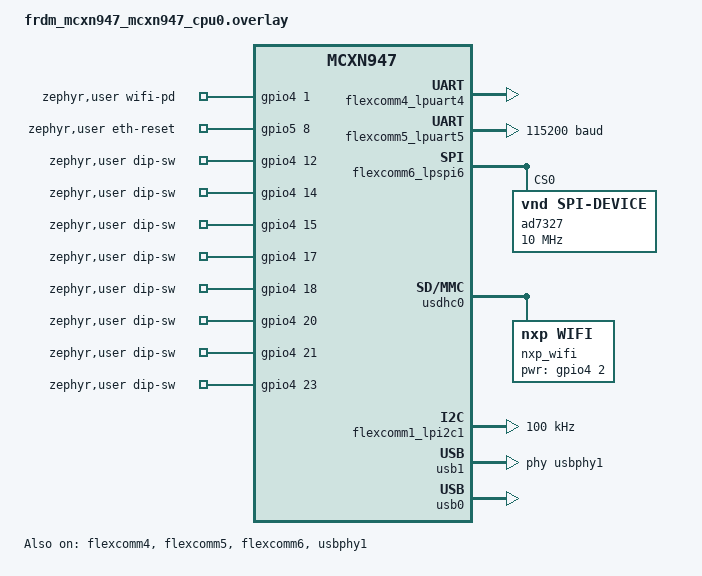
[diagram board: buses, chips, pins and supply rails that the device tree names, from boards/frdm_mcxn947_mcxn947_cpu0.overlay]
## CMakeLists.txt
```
# SPDX-License-Identifier: Apache-2.0

cmake_minimum_required(VERSION 3.20.0)

# boards/frdm_mcxn947_mcxn947_cpu0.overlay — Zephyr 자동 인식 (별도 지정 불필요)
find_package(Zephyr REQUIRED HINTS $ENV{ZEPHYR_BASE})
project(SmartGateway)

# USB HOST 스택 활성 시 링커가 __rom_start_address 심볼을 요구하나
# Zephyr 빌드 시스템이 defsym을 제공하지 않아 명시적으로 정의
if(CONFIG_USB_HOST_STACK)
  zephyr_ld_options(-Wl,--defsym=__rom_start_address=0x10000000)
endif()

target_sources(app PRIVATE src/main.c src/adc.c src/udp.c src/msgpack_adc.c src/time_helper.c src/rs232.c src/tcp_gateway.c src/sync_gate.c src/gw_error.c)

target_sources(app PRIVATE src/config_nvs.c src/network_manager.c src/dip_switch.c)

if(CONFIG_SMARTGATEWAY_DI_DO_ENABLE)
  target_sources(app PRIVATE src/di_do.c)
endif()

if(CONFIG_USB_HOST_STACK)
  target_sources(app PRIVATE src/ftdi_usb.c src/gas_sensor.c)
  # usbh_device.h (internal header) for usbh_device_get_any
  zephyr_include_directories(
    ${ZEPHYR_BASE}/subsys/usb/host
  )
endif()

if(CONFIG_SMARTGATEWAY_WIFI_ENABLE)
  target_sources(app PRIVATE src/wifi_manager.c)
endif()

# NXP WiFi 미들웨어(mlan_sdio.c, wlan.c)가 fsl_gpio.h 를 include 하지만
# wifi_nxp/CMakeLists.txt 에 drivers/gpio 경로가 없음.
# MCXN947 GPIO = nxp,kinetis-gpio → drivers/gpio/fsl_gpio.h 를 전역으로 추가.
if(CONFIG_WIFI_NXP)
  zephyr_include_directories(
    ${ZEPHYR_HAL_NXP_MODULE_DIR}/mcux/mcux-sdk-ng/drivers/gpio
  )
endif()
```

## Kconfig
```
# SPDX-License-Identifier: Apache-2.0
#
# SmartGateway 앱 옵션 — west build 전 menuconfig / prj.conf 로 조정

menu "SmartGateway"

config SMARTGATEWAY_LINE_ID
	string "UDP/MessagePack line / DeviceID (최대 50자)"
	default "HL-MAND-SENSOR-001"
	help
	  line·DeviveID 필드에 쓰입니다. 50자 초과는 잘립니다(NUL 종료).
	  prj.conf 예: CONFIG_SMARTGATEWAY_LINE_ID="이름"

comment "── NVS 분할 부팅 (net_boot_mode) ───────────────"

config SMARTGATEWAY_NET_BOOT_DEFAULT
	int "NVS 기본 네트워크 모드 (0=WiFi 1=이더넷)"
	default 0
	range 0 1
	help
	  스키마 초기화 후 또는 load_defaults 시 NVS에 쓰이는 초기값.
	  0=WiFi: 유선 내리고 WiFi만 시도. 전부 실패 시 NVS를 1로 바꾸고 냉 재부팅.
	  1=이더넷: WiFi 단계 없음.
	  WiFi 비활성 빌드에서는 항상 이더넷(1)으로 고정된다.

config SMARTGATEWAY_FORCE_ETH_BOOT_MODE
	bool "부팅 시 NVS net_boot_mode를 이더넷(1)로 저장"
	default n
	help
	  한 번 플래시 후 재부팅하면 NVS가 유선 우선 모드로 덮어써진다.
	  FORCE_WIFI_BOOT_MODE 와 동시에 사용할 수 없음(menuconfig 가 배타 처리).

config SMARTGATEWAY_FORCE_WIFI_BOOT_MODE
	bool "부팅 시 NVS net_boot_mode를 WiFi(0)로 저장"
	default n
	depends on SMARTGATEWAY_WIFI_ENABLE
	depends on !SMARTGATEWAY_FORCE_ETH_BOOT_MODE
	help
	  한 번 빌드·플래시 후 재부팅하면 NVS의 분할 부팅 모드가 WiFi로 덮어써진다.
	  WiFi 테스트 후에는 이 옵션을 끄고 다시 빌드하면 된다.

comment "── 이더넷 UDP ──────────────────────────────────"

config SMARTGATEWAY_ETH_UDP_PEER_IP
	string "이더넷 UDP 전송 목적지 IPv4"
	default "10.108.214.100"
	help
	  이더넷 인터페이스로 ADC 패킷을 보낼 상대 주소.
	  prj.conf: CONFIG_SMARTGATEWAY_ETH_UDP_PEER_IP="x.x.x.x"

config SMARTGATEWAY_ETH_UDP_PEER_PORT
	int "이더넷 UDP 전송 목적지 포트"
	default 20263
	range 1 65535

config SMARTGATEWAY_ETH_UDP_BIND_PORT
	int "이더넷 UDP 수신 바인드 포트 (0이면 recv 안 함)"
	default 0
	range 0 65535

comment "── 이더넷 보드 IP·TCP 상대 (netmgr / NVS 기본값) ──"

config SMARTGATEWAY_ETH_STATIC_IP
	string "이더넷 인터페이스 정적 IPv4 (보드)"
	default "10.108.214.150"

config SMARTGATEWAY_ETH_STATIC_NETMASK
	string "이더넷 서브넷 마스크"
	default "255.255.255.0"

config SMARTGATEWAY_ETH_STATIC_GW
	string "이더넷 기본 게이트웨이"
	default "10.108.214.1"

config SMARTGATEWAY_ETH_TCP_PEER_IP
	string "이더넷 TCP 상대(서버) IPv4"
	default "10.108.214.100"
	help
	  NVS의 eth_tcp_server_ip 기본값. TCP Modbus 게이트가 listen 할 때 상대 PC 주소.

config SMARTGATEWAY_ETH_TCP_PEER_PORT
	int "이더넷 TCP 상대 포트"
	default 20273
	range 1 65535

comment "── WiFi UDP ─────────────────────────────────────"

config SMARTGATEWAY_WIFI_UDP_PEER_IP
	string "WiFi UDP 전송 목적지 IPv4"
	default "192.168.5.100"
	help
	  WiFi 인터페이스로 ADC 패킷을 보낼 상대 주소.
	  prj.conf: CONFIG_SMARTGATEWAY_WIFI_UDP_PEER_IP="x.x.x.x"

config SMARTGATEWAY_WIFI_UDP_PEER_PORT
	int "WiFi UDP 전송 목적지 포트"
	default 20263
	range 1 65535

config SMARTGATEWAY_WIFI_UDP_BIND_PORT
	int "WiFi UDP 수신 바인드 포트 (0이면 recv 안 함)"
	default 0
	range 0 65535
	help
	  0 보다 크면 해당 포트에 bind 하고 recvfrom 으로 수신합니다.
	  SMARTGATEWAY_TCP_MODBUS_GATEWAY 사용 시 TCP MsgType 0x01(SYNC) 수신 전까지
	  UDP 수신은 하지 않습니다.

config SMARTGATEWAY_UDP_TEST_MODE
	bool "UDP 테스트 페이로드 (MessagePack array 4요소)"
	default n
	help
	  y이면 [ device_str, ts(17자), f32, f32 ] 형태의 MessagePack 배열만 전송합니다.
	  페이로드의 float 두 개는 항상 LPADC에서 읽은 snap->raw[0], raw[1] 실측값입니다.
	  운영(map)은 이 옵션을 끄면 됩니다.
	  prj.conf: CONFIG_SMARTGATEWAY_UDP_TEST_MODE=y

config SMARTGATEWAY_ADC_CHANNEL_COUNT
	int "LPADC 변환 채널 수 (1~8)"
	default 8
	range 1 8
	help
	  adc_task 가 변환하는 채널 개수(0..N-1, adc_inputs[] 와 순서 일치).
	  prj.conf 예: CONFIG_SMARTGATEWAY_ADC_CHANNEL_COUNT=2

config SMARTGATEWAY_RS232_ENABLE
	bool "RS-232 태스크 (UART ↔ MAX3232)"
	default n
	select SERIAL
	help
	  포트 0 = SmartGateway overlay 기준 flexcomm5 LPUART5 (MikroBUS P1_16 RX / P1_17 TX).
	  TCP Modbus 게이트웨이를 끄면 UDP(RS232_UDP_LISTEN_PORT) → UART 패스스루 스레드가 동작합니다.

if SMARTGATEWAY_RS232_ENABLE

config SMARTGATEWAY_RS232_BAUD_RATE
	int "RS-232 UART 보율 (bps)"
	default 115200

choice SMARTGATEWAY_RS232_DATA_BITS_CHOICE
	prompt "RS-232 데이터 비트"
	default SMARTGATEWAY_RS232_DATA_BITS_8
	help
	  기본 8비트 (8N1).

config SMARTGATEWAY_RS232_DATA_BITS_7
	bool "7"

config SMARTGATEWAY_RS232_DATA_BITS_8
	bool "8"
endchoice

choice SMARTGATEWAY_RS232_PARITY_CHOICE
	prompt "RS-232 패리티"
	default SMARTGATEWAY_RS232_PARITY_NONE
	help
	  기본 None (8N1).

config SMARTGATEWAY_RS232_PARITY_NONE
	bool "None"

config SMARTGATEWAY_RS232_PARITY_EVEN
	bool "Even"

config SMARTGATEWAY_RS232_PARITY_ODD
	bool "Odd"
endchoice

choice SMARTGATEWAY_RS232_STOP_BITS_CHOICE
	prompt "RS-232 정지 비트"
	default SMARTGATEWAY_RS232_STOP_BITS_1
	help
	  기본 1스톱.

config SMARTGATEWAY_RS232_STOP_BITS_1
	bool "1"

config SMARTGATEWAY_RS232_STOP_BITS_2
	bool "2"
endchoice

choice SMARTGATEWAY_RS232_FLOW_CTRL_CHOICE
	prompt "RS-232 흐름 제어"
	default SMARTGATEWAY_RS232_FLOW_CTRL_NONE
	help
	  기본 None. RTS/CTS는 보드/드라이버 배선이 있을 때만.

config SMARTGATEWAY_RS232_FLOW_CTRL_NONE
	bool "None"

config SMARTGATEWAY_RS232_FLOW_CTRL_RTS_CTS
	bool "RTS/CTS"
endchoice

config SMARTGATEWAY_RS232_UDP_LISTEN_PORT
	int "RS-232 패스스루 UDP 수신 포트 (이 장치에 bind)"
	default 20264
	range 1 65535
	help
	  TCP Modbus 게이트웨이가 꺼져 있을 때, 이 포트로 들어오는 UDP 페이로드를 RS-232 포트 0으로 전달합니다.
	  서버(또는 PC)가 게이트웨이 IP:이 포트로 바이트 스트림을 보내면 됩니다.

config SMARTGATEWAY_RS232_MODBUS_POST_TX_DELAY_MS
	int "Modbus RTU: UART TX 직후 수신 전 지연 (ms, 0=비활성)"
	default 0
	range 0 100
	help
	  RS-485 트랜시버는 TX 후 버스 방향 전환·라인 안착 시간이 필요할 수 있습니다.
	  수 ms 넣으면 슬레이브 첫 바이트 유실을 줄일 때가 있습니다. 풀듀플렉스 RS-232만 쓰면 0 권장.

endif

config SMARTGATEWAY_TCP_MODBUS_GATEWAY
	bool "TCP STX/Len/MsgType/Seq + Body + Error+ETX, RS-232 Modbus 중계"
	default n
	depends on SMARTGATEWAY_RS232_ENABLE
	select NET_TCP
	help
	  외곽 CRC 없음. Header 5B + Body(최대 256) + Tail(Error+ETX).
	  TCP_CLIENT_MODE=n 이면 보드가 listen(서버). y 이면 보드가 peer에 connect(클라이언트).
	  보드(클라이언트): 0x80 CONNECT(마스터+IDX+버전)를 HANDSHAKE_POLL_MS마다 송신.
	  서버: 0x01 SYNC(시각+RS-232). 보드: 0x81 ACK(Ret).
	  세션: 서버 0x02 Modbus 요청 → 보드 0x82(시각+응답).
	  RS-232 백그라운드 스레드(UDP 패스스루)는 띄우지 않습니다.

config SMARTGATEWAY_TCP_CLIENT_MODE
	bool "TCP 클라이언트: 원격 서버에 connect (보드는 클라이언트)"
	default y
	depends on SMARTGATEWAY_TCP_MODBUS_GATEWAY
	help
	  y이면 SMARTGATEWAY_TCP_PEER_IP:PEER_PORT 로 접속합니다. 원격(MCNX947 등)이
	  TCP 서버로 listen 해야 합니다.
	  n이면 SMARTGATEWAY_TCP_BIND_IP:LISTEN_PORT 에서 accept 하는 기존 동작입니다.

config SMARTGATEWAY_TCP_PEER_IP
	string "TCP peer IPv4 (클라이언트 모드: connect 대상 서버)"
	default "192.168.0.1"
	depends on SMARTGATEWAY_TCP_MODBUS_GATEWAY && SMARTGATEWAY_TCP_CLIENT_MODE

config SMARTGATEWAY_TCP_PEER_PORT
	int "TCP peer 포트 (클라이언트 모드)"
	default 5020
	range 1 65535
	depends on SMARTGATEWAY_TCP_MODBUS_GATEWAY && SMARTGATEWAY_TCP_CLIENT_MODE

config SMARTGATEWAY_TCP_RECONNECT_MS
	int "클라이언트: connect 실패·세션 종료 후 재시도 간격 (ms)"
	default 3000
	range 500 600000
	depends on SMARTGATEWAY_TCP_MODBUS_GATEWAY && SMARTGATEWAY_TCP_CLIENT_MODE

comment "── 이더넷 TCP ──────────────────────────────────"

config SMARTGATEWAY_ETH_TCP_BIND_IP
	string "이더넷 TCP listen 바인드 IPv4"
	default "0.0.0.0"
	depends on SMARTGATEWAY_TCP_MODBUS_GATEWAY && !SMARTGATEWAY_TCP_CLIENT_MODE

config SMARTGATEWAY_ETH_TCP_LISTEN_PORT
	int "이더넷 TCP listen 포트"
	default 20273
	range 1 65535
	depends on SMARTGATEWAY_TCP_MODBUS_GATEWAY && !SMARTGATEWAY_TCP_CLIENT_MODE

comment "── WiFi TCP ─────────────────────────────────────"

config SMARTGATEWAY_WIFI_TCP_BIND_IP
	string "WiFi TCP listen 바인드 IPv4"
	default "0.0.0.0"
	depends on SMARTGATEWAY_TCP_MODBUS_GATEWAY && !SMARTGATEWAY_TCP_CLIENT_MODE

config SMARTGATEWAY_WIFI_TCP_LISTEN_PORT
	int "WiFi TCP listen 포트"
	default 20273
	range 1 65535
	depends on SMARTGATEWAY_TCP_MODBUS_GATEWAY && !SMARTGATEWAY_TCP_CLIENT_MODE

config SMARTGATEWAY_PROTO_DEVICE_ID
	int "(예비) 프로토콜 Device ID — 현재 TCP 외곽 프레임에 미사용"
	default 1
	range 0 2147483647
	depends on SMARTGATEWAY_TCP_MODBUS_GATEWAY

config SMARTGATEWAY_TCP_HANDSHAKE_POLL_MS
	int "접속 통보(0x80) 송신 주기·수신 대기 (ms)"
	default 2000
	range 500 60000
	depends on SMARTGATEWAY_TCP_MODBUS_GATEWAY

config SMARTGATEWAY_TCP_CONNECT_MASTER
	string "CONNECT(0x80) Body: 장비 마스터 코드 (일반 문자, ASCII 바이트로 송신)"
	default "KRWJARDU002"
	depends on SMARTGATEWAY_TCP_MODBUS_GATEWAY
	help
	  예: KRWJARDU001 → 전선상 바이트 4B 52 57 … (문자별 ASCII, 덤프에서는 16진으로 보임).
	  NUL 제외·최대 SMARTGATEWAY_TCP_MAX_BODY 범위까지 복사 후 버전 헥사를 이어 붙입니다.
	  prj.conf: CONFIG_SMARTGATEWAY_TCP_CONNECT_MASTER="KRWJARDU001"

config SMARTGATEWAY_TCP_CONNECT_VERSION_HEX
	string "CONNECT(0x80) Body: 버전 등 (마스터 뒤에 이어 붙음, 연속 16진)"
	default "020000"
	depends on SMARTGATEWAY_TCP_MODBUS_GATEWAY
	help
	  기본 020000 = 바이트 02 00 00 (예: 2.0.0). 서버 규격에 맞게 변경.
	  최종 Body = 마스터(ASCII, 가변) + IDX(1B) + 버전(3B, 헥사 디코드). NVS master_code 우선.

config SMARTGATEWAY_TCP_MAX_BODY
	int "외곽 프레임 Body 최대 길이 (바이트, 규격 최대 256)"
	default 256
	range 0 256
	depends on SMARTGATEWAY_TCP_MODBUS_GATEWAY
	help
	  RS-232·TCP Body 상한. TCP_STREAM_BUF 는 (5 + 이 값 + 1) 이상 권장 (STX+Type+Seq+Len_BE+Body+ETX).

config SMARTGATEWAY_TCP_RS232_RX_TIMEOUT_MS
	int "RS-232 응답 수신 최대 대기 (ms, 첫 바이트~프레임 끝)"
	default 800
	range 100 86400000
	depends on SMARTGATEWAY_TCP_MODBUS_GATEWAY
	help
	  장치 자동 응답: 수백 ms. 수동 시험·느린 장치는 3600000(1시간) 등까지 설정 가능.

config SMARTGATEWAY_TCP_RS232_INTER_FRAME_GAP_MS
	int "RS-232 한 프레임 종료: 마지막 바이트 후 무음 시간 (ms)"
	default 50
	range 20 5000
	depends on SMARTGATEWAY_TCP_MODBUS_GATEWAY
	help
	  Modbus RTU 규격은 ~3.5 문자 시간(115200에서 수십 ms 미만). 수동 타이핑·느린 송신이면
	  1000~2000처럼 크게 설정(무음이 이 시간 지나면 수신 완료로 간주).

config SMARTGATEWAY_TCP_STREAM_BUF
	int "TCP 클라이언트 스트림 누적 버퍼 크기"
	default 512
	range 256 8192
	depends on SMARTGATEWAY_TCP_MODBUS_GATEWAY
	help
	  최소 권장: 5 + SMARTGATEWAY_TCP_MAX_BODY + 1 (한 프레임).

config SMARTGATEWAY_TCP_START_DELAY_MS
	int "TCP 게이트웨이 태스크 시작 전 지연 (ms)"
	default 0
	range 0 600000
	depends on SMARTGATEWAY_TCP_MODBUS_GATEWAY
	help
	  부팅 직후 다른 태스크·네트워크 준비 시간 확보용.


comment "보드(이 기기)의 고정 IPv4는 Zephyr 표준 옵션으로 prj.conf 에서 설정합니다:"
comment "  CONFIG_NET_CONFIG_MY_IPV4_ADDR, CONFIG_NET_CONFIG_MY_IPV4_GW, CONFIG_NET_CONFIG_MY_IPV4_NETMASK"

choice SMARTGATEWAY_NET_MODE
	prompt "네트워크 동작 모드"
	default SMARTGATEWAY_NET_MODE_BOTH
	help
	  prj.conf 에서 하나만 =y 로 설정하면 아래 항목이 자동 결정됩니다.
	    이더넷 IP 자동 설정(NET_CONFIG_SETTINGS)
	    WiFi 태스크 빌드(wifi_manager.c)

config SMARTGATEWAY_NET_MODE_ETH_ONLY
	bool "이더넷 전용"
	imply NET_CONFIG_SETTINGS

config SMARTGATEWAY_NET_MODE_WIFI_ONLY
	bool "WiFi 전용"

config SMARTGATEWAY_NET_MODE_BOTH
	bool "이더넷 + WiFi 동시"
	imply NET_CONFIG_SETTINGS

endchoice

config SMARTGATEWAY_WIFI_ENABLE
	bool
	default y if SMARTGATEWAY_NET_MODE_WIFI_ONLY || SMARTGATEWAY_NET_MODE_BOTH
	help
	  SMARTGATEWAY_NET_MODE 에서 자동 결정됩니다. 직접 수정하지 마세요.

if SMARTGATEWAY_WIFI_ENABLE

config SMARTGATEWAY_WIFI_SSID
	string "WiFi AP SSID"
	default "MyWiFi"
	help
	  연결할 AP의 SSID입니다.
	  prj.conf: CONFIG_SMARTGATEWAY_WIFI_SSID="내AP이름"

config SMARTGATEWAY_WIFI_PSK
	string "WiFi AP 비밀번호 (WPA2-PSK / WPA3-SAE 공용)"
	default ""
	help
	  WPA2-PSK 또는 WPA3-SAE 비밀번호. 아래 보안 방식에 따라 psk/sae_password 로 전달됩니다.
	  prj.conf: CONFIG_SMARTGATEWAY_WIFI_PSK="비밀번호"

choice SMARTGATEWAY_WIFI_SECURITY
	prompt "WiFi 보안 방식"
	default SMARTGATEWAY_WIFI_SECURITY_WPA2
	help
	  AP에 맞는 보안 방식을 선택합니다.

config SMARTGATEWAY_WIFI_SECURITY_NONE
	bool "Open (보안 없음)"

config SMARTGATEWAY_WIFI_SECURITY_WPA2
	bool "WPA2-PSK"

config SMARTGATEWAY_WIFI_SECURITY_WPA3
	bool "WPA3-SAE (자동 PWE: H2E + HNP)"

config SMARTGATEWAY_WIFI_SECURITY_WPA_AUTO
	bool "WPA2/WPA3 자동 (전환 AP 호환)"

endchoice

config SMARTGATEWAY_WIFI_STATIC_IP
	string "WiFi 인터페이스 정적 IPv4 주소"
	default "10.108.214.151"
	help
	  이더넷(NET_CONFIG_MY_IPV4_ADDR)과 충돌하지 않도록 별도 IP를 지정합니다.
	  prj.conf: CONFIG_SMARTGATEWAY_WIFI_STATIC_IP="x.x.x.x"

config SMARTGATEWAY_WIFI_STATIC_NETMASK
	string "WiFi 인터페이스 서브넷 마스크"
	default "255.255.255.0"

config SMARTGATEWAY_WIFI_STATIC_GW
	string "WiFi 인터페이스 기본 게이트웨이"
	default "10.108.214.1"

config SMARTGATEWAY_WIFI_TCP_PEER_IP
	string "WiFi TCP 상대(서버) IPv4"
	default "192.168.88.3"
	help
	  NVS의 wifi_tcp_server_ip 기본값.

config SMARTGATEWAY_WIFI_TCP_PEER_PORT
	int "WiFi TCP 상대 포트"
	default 20273
	range 1 65535

config SMARTGATEWAY_DEFER_WIFI_CONNECT_MS
	int "WiFi 연결 시도 전 추가 지연 (ms, 0=없음)"
	default 0
	range 0 600000
	help
	  네트워크 매니저가 WiFi 연결 전 대기하는 시간(RAM/crypto 피크 분산 등).

config SMARTGATEWAY_WIFI_WPA3_TRANSITION_AP
	bool "WPA3 전환(AP 혼합) — wifi 확장·문서용"
	default n

config SMARTGATEWAY_WIFI_WPA3_MFP_REQUIRED
	bool "PMF(802.11w) 필수 — wifi 확장·문서용"
	default n

config SMARTGATEWAY_WIFI_SCAN_BAND_2_4_GHZ
	bool "2.4GHz 대역만 스캔 — SCANNING 고착 회피 또는 2.4GHz 전용 AP"
	default n

config SMARTGATEWAY_WIFI_SCAN_BAND_5_GHZ
	bool "5GHz 대역만 스캔"
	default n
	depends on NXP_WIFI_5GHz_SUPPORT

config SMARTGATEWAY_WIFI_FIXED_CHANNEL
	int "고정 WiFi 채널 (0=전체 스캔)"
	default 0
	range 0 255

config SMARTGATEWAY_WIFI_TEST_NO_ETH
	bool "테스트: WiFi-only 오버레이(이더넷 생략·별도 conf와 함께)"
	default n
	help
	  일부 빌드에서 ETH를 제외할 때 netmgr 로그용. prj_wifi_only_test.conf 등과 함께 사용.

endif # SMARTGATEWAY_WIFI_ENABLE

config SMARTGATEWAY_WIFI_WIRING_EVB_MAYA
	bool "EVK-MAYA-W166 배선 (wifi_maya_rails.c 제외)"
	default n
	depends on SMARTGATEWAY_WIFI_ENABLE
	help
	  y이면 EVB-MAYA 전원 레일이 J3 VBUS_SDIO 로 공급되므로
	  wifi_maya_rails.c (P4_ GPIO 제어) 를 빌드에서 제외합니다.
	  prj.conf: CONFIG_SMARTGATEWAY_WIFI_WIRING_EVB_MAYA=y

comment "── DI/DO I2C GPIO 확장기 (PCA9554DB) ─────────────────────────────"

config SMARTGATEWAY_DI_DO_ENABLE
	bool "DI/DO I2C GPIO 확장기 활성화 (PCA9554DB)"
	default n
	depends on I2C
	help
	  DO: LPI2C1(FC1) P0_20/P0_21 → PCA9554DB(0x22), 8채널 디지털 출력
	  DI: LPI2C7(FC7) P3_2/P3_3   → PCA9554DB(0x21), 8채널 디지털 입력
	  EXT_PWR1: P0_24, EXT_PWR2: P0_25 GPIO 출력
	  HL-만도 빌드에서는 비활성(default n). 모드 플래그 ON 시만 NVS 연동.

endmenu

source "Kconfig.zephyr"
```

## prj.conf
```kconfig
# =============================================================================
# SmartGateway — FRDM-MCXN947 + MAYA-W166(IW416), WiFi 우선(WPA2/WPA3 AUTO) → ETH 폴백
#
# 시퀀스(netmgr): WiFi 최대 3회 → 이더넷 최대 3회 → 둘 다 실패 시 대기 후 다시 WiFi부터
# 통합 빌드: SMARTGATEWAY_WIFI_ONLY_TEST 사용 안 함(기본 OFF). WiFi-only 검증만 ON.
#
# 빌드:
#   west build -b frdm_mcxn947/mcxn947/cpu0 --pristine

# ---- 공통 -------------------------------------------------------------------
CONFIG_SMARTGATEWAY_LINE_ID="KRWJARDU001"
CONFIG_SMARTGATEWAY_PROTO_DEVICE_ID=0

# ---- TCP 공통 옵션 ----------------------------------------------------------
CONFIG_SMARTGATEWAY_TCP_MODBUS_GATEWAY=y
CONFIG_SMARTGATEWAY_TCP_CLIENT_MODE=y
# 클라이언트 폴백 peer (netmgr+NVS가 우선; 보통 WiFi PC 와 동일)
CONFIG_SMARTGATEWAY_TCP_PEER_IP="192.168.88.3"
CONFIG_SMARTGATEWAY_TCP_PEER_PORT=19195
CONFIG_SMARTGATEWAY_TCP_RECONNECT_MS=3000
# TCP 클라이언트 모드가 아니면 SMARTGATEWAY_TCP_RECONNECT_MS 는 비활성 — 설정 시 Kconfig 경고
CONFIG_SMARTGATEWAY_TCP_HANDSHAKE_POLL_MS=2000
CONFIG_SMARTGATEWAY_TCP_MAX_BODY=256
CONFIG_SMARTGATEWAY_TCP_RS232_RX_TIMEOUT_MS=10000
CONFIG_SMARTGATEWAY_TCP_RS232_INTER_FRAME_GAP_MS=1500
# 한 프레임 최소(5+256+2)보다 크게만 유지 — 512→384 로 정적 RAM 128B 절약
CONFIG_SMARTGATEWAY_TCP_STREAM_BUF=384
CONFIG_SMARTGATEWAY_TCP_START_DELAY_MS=5000

# ── IPv4 분할 프로파일 (NVS도 동일 구조로 저장·메뉴 편집) ────────────────────
#   WiFi 모드(NVS net_boot_mode=0): 보드 192.168.88.100 / PC 192.168.88.3 / TCP 20273
#   ETH 모드(NVS net_boot_mode=1): 보드 10.108.214.150 / PC 10.108.214.100 / TCP 20273
#   유선·무선 인터페이스는 Zephyr에서 별도; NVS의 wifi_* 와 eth_* 는 각 모드에서만 사용.
# NVS/시리얼 메뉴로 WiFi·이더넷 선택하려면 아래 둘 다 끄기(켜 있으면 매 부팅 NVS 덮어씀).

# =============================================================================
# ETH 프로파일 (유선 RJ45 — CONFIG_SMARTGATEWAY_ETH_*)
#  - 보드 ETH IP (SMARTGATEWAY_ETH_STATIC_*)
#  - UDP/TCP peer (ETH_*)
# =============================================================================
CONFIG_SMARTGATEWAY_ETH_STATIC_IP="10.108.214.150"
CONFIG_SMARTGATEWAY_ETH_STATIC_NETMASK="255.255.255.0"
CONFIG_SMARTGATEWAY_ETH_STATIC_GW="10.108.214.1"
# ETH UDP peer
CONFIG_SMARTGATEWAY_ETH_UDP_PEER_IP="10.108.214.100"
CONFIG_SMARTGATEWAY_ETH_UDP_PEER_PORT=19197
CONFIG_SMARTGATEWAY_ETH_UDP_BIND_PORT=0
# ETH TCP peer
CONFIG_SMARTGATEWAY_ETH_TCP_PEER_IP="10.108.214.100"
CONFIG_SMARTGATEWAY_ETH_TCP_PEER_PORT=19195

# =============================================================================
# WiFi 프로파일 (무선 IW416 — CONFIG_SMARTGATEWAY_WIFI_* , WIFI_ENABLE 시)
#  - 보드 WiFi IP (WIFI_STATIC_*)
#  - UDP/TCP peer (WIFI_*)
#
# 현재 시험 요구: WPA2/WPA3 AUTO. SCANNING 고착 시 앱 설정만으로 한계일 수 있음 → 아래 엔지니어링 대응.
#   - NXP IW416 + Zephyr wifi/wpa_supplicant 이슈 재현 패키지(로그·보드·SDK SHA)로 벤더 티켓
#   - Zephyr/NXP SDK·모노리식 WiFi 펌 업데이트 후 재검증
#   - SMARTGATEWAY_WIFI_ONLY_TEST 빌드로 ETH 제외 시 연결 여부( RAM/드라이버 분리 )
#   - PMF: REQUIRED(y)/OPTIONAL(n) 만 번갈아 시험(공유기 고급 802.11w 설정과 일치시키기)
# =============================================================================
CONFIG_SMARTGATEWAY_WIFI_SSID="HLMando2G"
CONFIG_SMARTGATEWAY_WIFI_PSK="HLmando2"
# WPA2/WPA3 혼합 AP 대응: WPA_AUTO_PERSONAL (로그 security=10).
CONFIG_SMARTGATEWAY_WIFI_SECURITY_WPA_AUTO=y
# CONFIG_SMARTGATEWAY_WIFI_SECURITY_WPA3 is not set
# PMF: 공유기가 필수 PMF면 y 로 시험. register_frame 미지원 로그와 충돌 시 n 유지 후 NXP 문의.
# WiFi 첫 시도 전 지연(ms): NVS/콘솔·WPA2/WPA3·통합 빌드 crypto/RAM 피크 분산
CONFIG_SMARTGATEWAY_DEFER_WIFI_CONNECT_MS=2000
# 대역 선택: 둘 다 n → WIFI_FREQ_BAND_UNKNOWN (2.4+5GHz 듀얼밴드)
# 2.4GHz 전용 AP(SCANNING 고착 회피): SCAN_BAND_2_4_GHZ=y
# 5GHz 전용 AP: SCAN_BAND_5_GHZ=y (SSID도 5GHz AP 것으로 변경)
CONFIG_SMARTGATEWAY_WIFI_SCAN_BAND_2_4_GHZ=n
# CONFIG_SMARTGATEWAY_WIFI_SCAN_BAND_5_GHZ=y
# AP 채널을 알면 1~13(2.4GHz) 또는 36~165(5GHz) 지정(0=전 채널 스캔)
CONFIG_SMARTGATEWAY_WIFI_FIXED_CHANNEL=0

# 공유기 LAN 192.168.88.0/24 (게이트웨이 .1). 보드 정적 IP는 DHCP와 겹치지 않게 설정.
CONFIG_SMARTGATEWAY_WIFI_STATIC_IP="192.168.88.100"
CONFIG_SMARTGATEWAY_WIFI_STATIC_NETMASK="255.255.255.0"
CONFIG_SMARTGATEWAY_WIFI_STATIC_GW="192.168.88.1"

# TCP/UDP 서버가 떠 있는 PC (동일 서브넷, 예: 192.168.88.3)
CONFIG_SMARTGATEWAY_WIFI_UDP_PEER_IP="192.168.88.3"
CONFIG_SMARTGATEWAY_WIFI_UDP_PEER_PORT=19197
CONFIG_SMARTGATEWAY_WIFI_UDP_BIND_PORT=19197
CONFIG_SMARTGATEWAY_WIFI_TCP_PEER_IP="192.168.88.3"
CONFIG_SMARTGATEWAY_WIFI_TCP_PEER_PORT=19195

# =============================================================================
# RS-232
# =============================================================================
CONFIG_SMARTGATEWAY_RS232_ENABLE=y
CONFIG_SMARTGATEWAY_RS232_BAUD_RATE=115200
CONFIG_SMARTGATEWAY_RS232_DATA_BITS_8=y
CONFIG_SMARTGATEWAY_RS232_PARITY_NONE=y
CONFIG_SMARTGATEWAY_RS232_STOP_BITS_1=y
CONFIG_SMARTGATEWAY_RS232_FLOW_CTRL_NONE=y
CONFIG_SMARTGATEWAY_RS232_UDP_LISTEN_PORT=20263
CONFIG_SMARTGATEWAY_RS232_MODBUS_POST_TX_DELAY_MS=2

CONFIG_SPI=y
CONFIG_I2C=y
# PCA9554DB DI/DO I2C GPIO 확장기 테스트 (HL-만도 외 기능, 기본 n)
CONFIG_SMARTGATEWAY_DI_DO_ENABLE=n
# DMA 채널 미설정 → CPU 폴링 모드 강제 (DMA 사용 시 HardFault)
CONFIG_SPI_NXP_LPSPI_DMA=n
# printf %f 지원 활성화
CONFIG_CBPRINTF_FP_SUPPORT=y
# AD7327 외부 SPI ADC 8채널 (±10V, LPSPI6 FlexComm6)
CONFIG_SMARTGATEWAY_ADC_CHANNEL_COUNT=8

# main(): printf·NVS·netmgr 대기 — 1792에서 스택 침범 시 부팅 로그/동작 이상 가능
CONFIG_MAIN_STACK_SIZE=2560
CONFIG_REGULATOR=y
CONFIG_GPIO=y
CONFIG_MDIO=y

# =============================================================================
# NVS + 부팅 콘솔 설정 메뉴
# =============================================================================
CONFIG_NVS=y
CONFIG_REBOOT=y
CONFIG_FLASH=y
CONFIG_FLASH_MAP=y
CONFIG_FLASH_PAGE_LAYOUT=y
CONFIG_CONSOLE_SUBSYS=y
CONFIG_CONSOLE_GETCHAR=y

# =============================================================================
# WiFi 드라이버 — ETH 단독 테스트 시 아래 전체를 n/주석 처리
# =============================================================================
CONFIG_WIFI=y
CONFIG_WIFI_NXP=y
CONFIG_NXP_MONOLITHIC_WIFI=y
CONFIG_NXP_IW416=y
CONFIG_NXP_IW416_UBX_MAYA_W1_USD=y
CONFIG_NXP_IW416_REGION_WW=y
CONFIG_WIFI_NM_WPA_SUPPLICANT=y
CONFIG_WIFI_NM_WPA_SUPPLICANT_CRYPTO_ALT=y
# WPA2/WPA3 + TLS: mbedTLS·hostap RAM 피크 — 힙·WPA 스택 우선 (ETH 폴백은 net_buf 일부로 재분배)
CONFIG_MBEDTLS=y
CONFIG_MBEDTLS_MD_C=y
CONFIG_MBEDTLS_PKCS5_C=y
CONFIG_MBEDTLS_SHA1=y
# WPA supplicant thread stack: 10240/11264/12288 failed to connect; 13312 (field test)
CONFIG_WIFI_NM_WPA_SUPPLICANT_THREAD_STACK_SIZE=13312
# 링크 통과: WPA2/WPA3 피크에서 malloc 실패 시 소폭 상향(그 전에 NET_BUF/스택 로그 확인)
# RAM noinit overflow(~수백 B) 시 힙 소폭 감소 — WPA3 연결 실패 로그 나오면 +256~512 만 되돌림
CONFIG_HEAP_MEM_POOL_SIZE=63488
# 소프트 로밍 off: 코드·런타임 RAM 절약, 초기 연결 시 백그라운드 스캔 경합 완화
CONFIG_NXP_WIFI_ROAMING=n
CONFIG_NXP_WIFI_CSI=n
CONFIG_NXP_WIFI_IPV6=n
# Dual-band WiFi is required; keep 5 GHz enabled and limit only scan entries.
CONFIG_NXP_WIFI_MAX_AP_ENTRIES=4
CONFIG_NXP_WIFI_5GHz_SUPPORT=y
CONFIG_NXP_WIFI_WLCMGR_TASK_STACK_SIZE=5120
CONFIG_NXP_WIFI_MON_TASK_STACK_SIZE=3072
CONFIG_NXP_WIFI_DRIVER_TASK_STACK_SIZE=2048

# =============================================================================
# 네트워크 스택
# =============================================================================
CONFIG_NETWORKING=y
CONFIG_NET_MGMT_EVENT_QUEUE_SIZE=8
CONFIG_NET_IPV4=y
CONFIG_NET_IPV6=n
CONFIG_NET_IF_MAX_IPV4_COUNT=2
CONFIG_NET_UDP=y
CONFIG_NET_TCP=y
CONFIG_NET_SOCKETS=y
CONFIG_NET_L2_ETHERNET=y
# NXP WiFi 미들웨어가 net_dhcpv4_* 심볼을 참조하므로 활성 유지 필요
CONFIG_NET_DHCPV4=y
# 이더넷+TCP(게이트웨이) 동시에 NET 스레드 부하 증가 — 1536→2048, TCP 워크큐·ENET RX 상향
CONFIG_NET_TX_STACK_SIZE=2048
CONFIG_NET_RX_STACK_SIZE=2048
CONFIG_NET_TCP_WORKQ_STACK_SIZE=2048
CONFIG_ETH_NXP_ENET_QOS_RX_THREAD_STACK_SIZE=2048

# NET_CONFIG_SETTINGS 비활성: IP 자동 할당 없음, 30초 부팅 지연 없음
# network_manager.c 가 ETH/WiFi IP를 직접 할당한다.
CONFIG_NET_CONFIG_SETTINGS=n

# Hostname is selected by the socket/POSIX network stack.
CONFIG_NET_HOSTNAME_ENABLE=y
CONFIG_NET_HOSTNAME="smartgateway"

CONFIG_LOG=y
CONFIG_LOG_BUFFER_SIZE=1280
CONFIG_LOG_DEFAULT_LEVEL=3
CONFIG_WIFI_LOG_LEVEL_INF=y
# eth_nxp_enet_qos_mac: RECV failed on pkt (LOG_WRN) 숨김 — PHY는 CONFIG_PHY_LOG_LEVEL 유지
CONFIG_ETHERNET_LOG_LEVEL_ERR=y
CONFIG_SDHC_LOG_LEVEL_WRN=y
CONFIG_SD_LOG_LEVEL_WRN=y


# =============================================================================
# USB HOST — FT2232 가스 센서 (O2/H2S/CO)
# USB1 EHCI HS HOST 컨트롤러 + 실험적 USB HOST 스택
# =============================================================================
CONFIG_UHC_NXP_EHCI=n
CONFIG_UHC_NXP_KHCI=n
CONFIG_USB_HOST_STACK=n
CONFIG_USBH_STACK_SIZE=2048
CONFIG_UHC_NXP_THREAD_STACK_SIZE=4096
# UHC net_buf 풀: VAR 풀(공유)로 USB1+USB0 동시 사용 시 충분한 여유 확보
# ENOMEM 원인 진단: xfer_alloc (ep_desc NULL / slab 고갈) vs buf_alloc (풀 고갈)
# → ftdi_usb.c 에 LOG_ERR 추가함: 빌드 후 로그에서 "xfer_alloc failed" vs "buf_alloc failed" 확인
CONFIG_UHC_BUF_POOL_SIZE=4096
CONFIG_UHC_BUF_COUNT=64
# xfer slab: setup(x4)+bulk 동시 16개로 부족 가능 → 32개
CONFIG_UHC_XFER_COUNT=32
# USB0+USB1 동시 열거(~6 ctrl xfer each) + bulk 이벤트 → 기본 10으로 포화 → 이벤트 드롭 → 2s 타임아웃
CONFIG_USBH_MAX_UHC_MSG=32
```

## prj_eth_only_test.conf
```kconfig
# 프래그먼트: prj.conf 이후 병합 — 이더넷만으로 L2·정적 IP·TCP/UDP 검증
#   west build ... -d build-eth --pristine -- -DSMARTGATEWAY_ETH_ONLY_TEST=ON
#
# WiFi 드라이버·blob 비활성 (hal wireless CMake 가 IW416 blob 을 찾지 않게 NXP_MONOLITHIC_WIFI=n 필수)
CONFIG_WIFI=n
CONFIG_NXP_MONOLITHIC_WIFI=n

# ETH 단독이면 힙 여유 (링크 실패 시 이전 통합 빌드 값에 맞춤)
CONFIG_HEAP_MEM_POOL_SIZE=49152
```

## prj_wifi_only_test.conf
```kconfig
# 프래그먼트: 위에 prj.conf + 아래 DTS 오버레이와 함께 쓸 것 (WiFi 검증 빌드)
#   -DEXTRA_DTC_OVERLAY_FILE=boards/frdm_mcxn947_mcxn947_cpu0.wifi_test_no_eth.overlay
#
CONFIG_SMARTGATEWAY_WIFI_TEST_NO_ETH=y
```

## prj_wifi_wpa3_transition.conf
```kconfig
# 혼합(WPA2+WPA3) 공유기에서만: prj.conf 의 TRANSITION=n 을 덮어써 y 로 켤 때 사용
#   west build ... -- -DEXTRA_CONF_FILE=.../prj_wifi_wpa3_transition.conf
# 내용: CONFIG_SMARTGATEWAY_WIFI_WPA3_TRANSITION_AP=y
CONFIG_SMARTGATEWAY_WIFI_WPA3_TRANSITION_AP=y
```

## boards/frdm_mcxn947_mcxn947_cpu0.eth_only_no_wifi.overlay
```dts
/*
 * 이더넷 단독 검증: USDHC0(SDMAY IW416 SDIO) 비활성 → WiFi 펌웨어·SDIO 로그 제거, RAM 절약
 * CMake: -DSMARTGATEWAY_ETH_ONLY_TEST=ON
 */

&usdhc0 {
	status = "disabled";
};
```

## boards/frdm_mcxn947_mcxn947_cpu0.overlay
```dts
/*
 * SmartGateway — 커스텀 PCB (MCXN947) + MAYA-W160-001B (IW416)
 *
 * WiFi 연결: USDHC0(SDIO) — MAYA-W160-001B
 *   SDIO 핀만 연결: CLK, CMD, D0~D3 + VBUS_SDIO(3.3V)
 *   GPIO 없음: PDn은 풀업으로 HIGH (정상동작)
 *
 * UART0(FC4): P1_8=RX, P1_9=TX (콘솔 or RS-232 포트0)
 * UART1(FC5): P1_16=RX, P1_17=TX (RS-232 포트1)
 * ADC       : LPADC0 — ADC0_A0(CH0A), ADC0_B0(CH0B)
 * [AD7327]  : LPSPI6(FC6) — 아래 주석 블록 참조, 추후 활성화
 *
 * NVS       : 외부 W25Q64 없음 → 내부 플래시 끝 64KB (0x1F0000~0x1FFFFF)
 */

/* cpu1 미사용: SRAM0-7 전체(416KB)를 cpu0 에 할당 */
&sram0 {
	reg = <0x20000000 DT_SIZE_K(416)>;
};

/* ── LPADC0 비활성화 — AD7327 SPI ADC로 교체 ── */
&lpadc0 {
	status = "disabled";
};

/* ── SAI1 비활성화 — P3_20/P3_21 핀이 LPSPI6(FC6)와 공유 ── */
&sai1 {
	status = "disabled";
};

/* ── UART0: flexcomm4 (P1_8/P1_9, 콘솔 or RS-232 포트0) ── */
&flexcomm4 {
	status = "okay";
};

&flexcomm4_lpuart4 {
	status = "okay";
};

/* ── UART1: flexcomm5 (P1_16/P1_17, RS-232 포트1) ── */
&pinctrl {
	pinmux_smartgateway_rs232_mikrobus: pinmux_smartgateway_rs232_mikrobus {
		group0 {
			pinmux = <0x14000200 0x14400200>;
			slew-rate = "fast";
			drive-strength = "low";
			input-enable;
			bias-pull-up;
		};
	};
};

&i3c1 {
	status = "disabled";
};

&flexcomm5 {
	status = "okay";
};

&flexcomm5_lpuart5 {
	status = "okay";
	current-speed = <115200>;
	pinctrl-0 = <&pinmux_smartgateway_rs232_mikrobus>;
	pinctrl-names = "default";
};

&dac0 {
	status = "disabled";
};

/* ── AD7327 SPI ADC: LPSPI6 (FlexComm6) — P3_20/21/22/23 ──────────
 * N9X_MUX('3',pin,3) = FC6 function:
 *   P3_20 FC6_MOSI = 0x35000300
 *   P3_21 FC6_CLK  = 0x35400300
 *   P3_22 FC6_MISO = 0x35800300
 *   P3_23 FC6_CS = 0x35C00300
 */
&pinmux_flexcomm6_lpspi {
	group0 {
		pinmux = <0x35000300>,	/* FC6_P0 MOSI P3_20 */
				 <0x35400300>,	/* FC6_P1 CLK  P3_21 */
				 <0x35800300>,	/* FC6_P2 MISO P3_22 */
				 <0x35C00300>;	/* FC6_P3 CS   P3_23 */
		slew-rate = "fast";
		drive-strength = "low";
		input-enable;
	};
};

&flexcomm6 {
	status = "okay";
};

&flexcomm6_lpspi6 {
	status = "okay";
	pinctrl-0 = <&pinmux_flexcomm6_lpspi>;
	pinctrl-names = "default";
	/* LP_FLEXCOMM6_IRQn = 41 (MCXN947 인터럽트 벡터)
	 * 미설정 시 SPI 전송 완료 인터럽트 → 핸들러 없음 → HardFault */
	interrupts = <41 0>;

	ad7327: ad7327@0 {
		compatible = "vnd,spi-device";
		reg = <0>;
		spi-max-frequency = <10000000>;	/* 10 MHz */
	};
};

/* ── USDHC0 — SDIO (MAYA-W160-001B IW416 WiFi) ── */
&usdhc0 {
	status = "okay";
	/delete-property/ cd-gpios;
	max-bus-freq = <1000000>;
	/delete-node/ sdmmc;

	nxp_wifi: nxp-wifi {
		compatible = "nxp,wifi";
		/*
		 * pwr-gpios: P4_2 — WiFi 모듈 RESET 핀
		 *   HIGH = 모듈 활성(reset 해제), LOW = 모듈 리셋
		 *   P4_2 기본 mux = GPIO(mux0), 별도 pinctrl 불필요
		 *
		 *   PCB 배선이 반전(P4_2 LOW = 모듈 활성)이면
		 *   GPIO_ACTIVE_HIGH → GPIO_ACTIVE_LOW 로 변경
		 */
		pwr-gpios = <&gpio4 2 GPIO_ACTIVE_HIGH>;
	};
};

/* ── ENET RMII 핀 전체 재정의 (커스텀 PCB) ───────────────────────────
 * FRDM 기본값과 비교:
 *   MDC  : FRDM P1_20 → 커스텀 P1_2   (변경)
 *   MDIO : FRDM P1_21 → 커스텀 P1_3   (변경)
 *   나머지 mac_group(TX_CLK/TXEN/TXD0/TXD1/RXDV/RXD0/RXD1): FRDM와 동일
 *
 * FRDM 기본 mac_group이 DTS 병합 시 소실될 수 있어 여기서 명시적으로 재정의.
 *
 * N9X_MUX(port, pin, mux) = ((port-'0')<<28) | (pin<<22) | (mux<<8)
 *   P1_x func9 계산: 0x10000900 | (pin<<22)
 *   MDC  P1_2  = 0x10800900   MDIO P1_3  = 0x10C00900
 *   CLK  P1_4  = 0x11000900   TXEN P1_5  = 0x11400900
 *   TXD0 P1_6  = 0x11800900   TXD1 P1_7  = 0x11C00900
 *   RXDV P1_13 = 0x13400900   RXD0 P1_14 = 0x13800900
 *   RXD1 P1_15 = 0x13C00900
 */
&pinmux_enet_qos {
	mdio_group {
		pinmux = <0x10800900>,	/* ENET0_MDC  P1_2,  func9 */
				 <0x10C00900>;	/* ENET0_MDIO P1_3,  func9 */
		slew-rate = "fast";
		drive-strength = "low";
		input-enable;
	};

	mac_group {
		pinmux = <0x11000900>,	/* ENET0_TX_CLK P1_4,  func9  REF_CLK 50MHz */
				 <0x11400900>,	/* ENET0_TXEN   P1_5,  func9 */
				 <0x11800900>,	/* ENET0_TXD0   P1_6,  func9 */
				 <0x11C00900>,	/* ENET0_TXD1   P1_7,  func9 */
				 <0x13400900>,	/* ENET0_RXDV   P1_13, func9 */
				 <0x13800900>,	/* ENET0_RXD0   P1_14, func9 */
				 <0x13C00900>;	/* ENET0_RXD1   P1_15, func9 */
		slew-rate = "fast";
		drive-strength = "low";
		input-enable;
	};
};

/* ── LPI2C1 (FC1 I2C): DO_I2C — PCA9554DB DO 8채널 ─────────────────────
 * P0_20 = FC1_P0 SDA (func3) = N9X_MUX('0',20,3)
 * P0_21 = FC1_P1 SCL (func3) = N9X_MUX('0',21,3)
 * FRDM Arduino SPI(FC1_LPSPI1) 비활성 → I2C로 교체
 */
&pinctrl {
	pinmux_flexcomm1_lpi2c: pinmux_flexcomm1_lpi2c {
		group0 {
			pinmux = <0x05000300>,	/* FC1_P0 SDA P0_20, func3 */
					 <0x05400300>;	/* FC1_P1 SCL P0_21, func3 */
			slew-rate = "fast";
			drive-strength = "low";
			input-enable;
			bias-pull-up;
			drive-open-drain;
		};
	};
};

/* FRDM Arduino SPI — 커스텀 PCB 미사용, LPI2C1으로 대체 */
&flexcomm1_lpspi1 {
	status = "disabled";
};

&flexcomm1_lpi2c1 {
	status = "okay";
	pinctrl-0 = <&pinmux_flexcomm1_lpi2c>;
	pinctrl-names = "default";
	clock-frequency = <100000>;
};

/* ── LPI2C7 (FC7 I2C): DI_I2C — PCA9554DB DI 8채널 ─────────────────────
 * FRDM base DTS(frdm_mcxn947.dtsi)에서 이미 P3_2(SDA)/P3_3(SCL)으로 설정됨.
 * overlay 추가 불필요 — flexcomm7/lpi2c7 status="okay", pinctrl 기 완성.
 */

/* ── GPIO0 (EXT_PWR1 P0_24 / EXT_PWR2 P0_25) ───────────────────────── */
&gpio0 {
	status = "okay";
};

/* ── GPIO3 (DO_INT P3_0 / DI_INT P3_1 입력) ────────────────────────── */
&gpio3 {
	status = "okay";
};

/* ── DIP 스위치 8개 (GPIO4) ─────────────────────────────────────────
 * SW1~SW7: 7비트 이진수 → 장치코드 번호 (0=NVS사용, 1~127=코드선택)
 * SW8: 인덱스 (OFF=0, ON=1)
 * ON = 3.3V = GPIO_ACTIVE_HIGH
 */
&gpio4 {
	status = "okay";
};

/* ── WiFi PDn 제어 GPIO (P4_1) + LAN8741A nRST (P5_8) ──────────────
 * wifi-pd-gpios: P4_1(WiFi PDn) — PDn 미제어 시 모듈 파워다운 → wlan_init -1
 * eth-reset-gpios: P5_8 → LAN8741A /ETH_RESET (ACTIVE_HIGH: HIGH=동작, LOW=리셋)
 *   SYS_INIT(POST_KERNEL, 50) 에서 50ms 토글 → PHY 완전 초기화
 */
/ {
	zephyr,user {
		/* WiFi Reset SW */
		wifi-pd-gpios  = <&gpio4 1 GPIO_ACTIVE_HIGH>;
		/* LAN8741A nRST: P5_8, HIGH=동작 LOW=리셋 */
		eth-reset-gpios = <&gpio5 8 GPIO_ACTIVE_HIGH>;
		/* DIP 스위치: SW1~SW8 순서, GPIO_ACTIVE_HIGH (ON=3.3V=1) */
		dip-sw-gpios   = <&gpio4 12 GPIO_ACTIVE_HIGH>,  /* SW1 bit0 */
				 		 <&gpio4 14 GPIO_ACTIVE_HIGH>,  /* SW2 bit1 */
				 		 <&gpio4 15 GPIO_ACTIVE_HIGH>,  /* SW3 bit2 */
						 <&gpio4 17 GPIO_ACTIVE_HIGH>,  /* SW4 bit3 */
				 		 <&gpio4 18 GPIO_ACTIVE_HIGH>,  /* SW5 bit4 */
				 		 <&gpio4 20 GPIO_ACTIVE_HIGH>,  /* SW6 bit5 */
				 		 <&gpio4 21 GPIO_ACTIVE_HIGH>,  /* SW7 bit6 */
				 		 <&gpio4 23 GPIO_ACTIVE_HIGH>;  /* SW8 인덱스 */
	};
};

/* ── ENET MAC 주소 ──────────────────────────────────────────────────────
 * nxp,unique-mac: 칩 UID(128bit) → CRC24 해시 → NXP OUI + 3B
 *   부팅마다 동일, 보드마다 고유 → 산업 현장 MAC 등록 대응
 *   특정 MAC 고정 필요 시: local-mac-address = [xx xx xx xx xx xx];
 */
&enet_mac {
	/delete-property/ zephyr,random-mac-address;
	nxp,unique-mac;
};

/* ── LAN8741A PHY 리셋 순서 ────────────────────────────────────────────
 * 1) SYS_INIT(POST_KERNEL 50): P5_8 nRST 하드웨어 리셋 (50ms LOW → HIGH → 100ms)
 *    → PHY 완전 초기화, RMIISEL=1 재샘플 → RMII 모드 확정
 * 2) phy_mii_init(~POST_KERNEL 90): BMCR bit15 소프트 리셋 → ANAR=0x01E1 → AN 재시작
 *    → 하드웨어 리셋 후이므로 ETIMEDOUT 없이 정상 완료
 */
&phy {
};

/* ── GPIO5 활성화 (LAN8741A nRST P5_8 사용) ── */
&gpio5 {
	status = "okay";
};

/* ── 외부 QSPI 플래시 없음 (커스텀 PCB에 W25Q64 미실장) ── */
&flexspi {
	status = "disabled";
};

/* storage_partition 라벨을 내부 플래시로 재할당하기 위해 W25Q64 파티션 노드 제거 */
&w25q64jvssiq {
	status = "disabled";
	/delete-node/ partitions;
};

/*
 * 내부 플래시 NVS 파티션 — slot1(CPU1/OTA 미사용) 끝 64KB를 분리
 *
 * 주소맵 (내부 플래시 2MB):
 *   0x000000 ~ 0x013FFF :  80KB  boot_partition   (MCUboot 미사용이므로 공백)
 *   0x014000 ~ 0x109FFF : 984KB  slot0_partition  ← 앱 코드
 *   0x10A000 ~ 0x1EFFFF : 920KB  slot1_partition  (CPU1/OTA 미사용, 변경없이 확보)
 *   0x1F0000 ~ 0x1FFFFF :  64KB  storage_partition ← NVS (8섹터 × 8KB)
 */
&flash {
	partitions {
		slot1_partition: partition@10A000 {
			reg = <0x0010A000 DT_SIZE_K(920)>;
		};
		storage_partition: partition@1F0000 {
			label = "storage";
			reg = <0x001F0000 DT_SIZE_K(64)>;
		};
	};
};

/* ── USB1 HOST (EHCI High-Speed) — FT2232 #1 (센서) ────────────────
 * CON201(Molex 67298-4090) USB1 포트 → FT2232 UART→O2-SM30-3V, H2S-SM30, CO-SM30, CH4-S3-3V, S300-S3-3V
 */
&usb1 {
	compatible = "nxp,uhc-ehci";
	phy-handle = <&usbphy1>;
	/delete-property/ num-bidir-endpoints;
	status = "okay";
};

&usbphy1 {
	status = "okay";
	tx-d-cal = <4>;
	tx-cal-45-dp-ohms = <7>;
	tx-cal-45-dm-ohms = <7>;
};

/* ── USB0 HOST (KHCI Full-Speed) — FT2232 #2 (AM1002 센서) ────────────
 * CON201 USB0 포트 → FT2232 UART→AM1002 센서
 * USB0 D+/D-는 전용 핀(별도 pinctrl 불필요)
 * 클럭: board.c 에서 kCLK_48M_to_USB0 → 48MHz FRO_HF 공급
 */
&usb0 {
	compatible = "nxp,uhc-khci";
	/delete-property/ num-bidir-endpoints;
	/delete-property/ no-voltage-regulator;
	status = "okay";
};
```

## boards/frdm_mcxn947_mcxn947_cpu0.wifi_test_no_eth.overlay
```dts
/*
 * WiFi 전용 테스트: 보드 내장 이더넷(ENET QoS) 디바이스 비활성화
 * ─ ENET 컨트롤러/RX 디스크립터 버퍼/PHY 스택이 빌드·RAM에서 빠짐
 * ─ 케이블 꽂여 있어도 MAC이 안 올라와 WiFi 디버깅에 유리함
 *
 * CMakeLists 에서 CMake 옵션 SMARTGATEWAY_WIFI_ONLY_TEST=ON 일 때 자동으로 이 오버레이 +
 * prj_wifi_only_test.conf 가 붙음. 수동 빌드:
 *   west build ... -d debug-wifi-test --pristine -- -DSMARTGATEWAY_WIFI_ONLY_TEST=ON
 */

&enet {
	status = "disabled";
};

&enet_mac {
	status = "disabled";
};

&enet_mdio {
	status = "disabled";
};

&phy {
	status = "disabled";
};
```

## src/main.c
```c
/*
 * 2026.03.18
 * Smart Gateway - Main
 * 작성자 : LYH
 */

#include <stdio.h>
#include <zephyr/kernel.h>
#include <zephyr/sys/util.h>
#include <zephyr/autoconf.h>

#include "adc.h"
#include "rs232.h"
#include "tcp_gateway.h"
#include "udp.h"
#include "config_nvs.h"
#include "network_manager.h"
#include "dip_switch.h"
#ifdef CONFIG_SMARTGATEWAY_DI_DO_ENABLE
#include "di_do.h"
#endif
#ifdef CONFIG_USB_HOST_STACK
#include "gas_sensor.h"
#endif

#define SmartGateway_VERSION "V2.0.0(HL-Mando)"

#if IS_ENABLED(CONFIG_WIFI_NXP)
#  define NET_MODE_STR "WiFi ([u-blox] MAYA-W160-001B(IW416))"
#else
#  define NET_MODE_STR "Ethernet Only"
#endif

int main(void)
{

	printf("\n*** Smart Gateway %s ***\n", SmartGateway_VERSION);
	printf("Network: %s\n", NET_MODE_STR);

	config_nvs_load();

	/* DIP 스위치: NVS 로드 후 필요 시 덮어쓰기 */
	dip_switch_apply();

	printf("[CFG] NVS summary - boot mode %u (%s)\n",
	       (unsigned int)g_gw_config.net_boot_mode,
	       g_gw_config.net_boot_mode == 1U ? "next boot Ethernet" : "next boot WiFi");
	printf("      Device code: %s  |  Index: %u\n", g_gw_config.master_code,
	       (unsigned)g_gw_config.device_index);
	printf("      WiFi  board %s | PC TCP %s:%u | UDP %s:%u\n",
	       g_gw_config.wifi_ip, g_gw_config.wifi_tcp_server_ip,
	       (unsigned)g_gw_config.wifi_tcp_server_port,
	       g_gw_config.wifi_udp_server_ip, (unsigned)g_gw_config.wifi_udp_server_port);
	printf("      ETH   board %s | PC TCP %s:%u | UDP %s:%u\n",
	       g_gw_config.eth_ip, g_gw_config.eth_tcp_server_ip,
	       (unsigned)g_gw_config.eth_tcp_server_port,
	       g_gw_config.eth_udp_server_ip, (unsigned)g_gw_config.eth_udp_server_port);

#ifdef CONFIG_SMARTGATEWAY_DI_DO_ENABLE
	if (di_do_init() != 0) {
		printf("[MAIN] DI/DO init failed\n");
	}
#endif

	/* USB HOST(FT2232 가스 센서): NVS 메뉴 전 시작 → 메뉴 내 T키로 즉시 확인 가능 */
#ifdef CONFIG_USB_HOST_STACK
	gas_sensor_start();
#endif

	config_nvs_menu();

	printf("[MAIN] NVS network mode: %u (0=WiFi 1=ETH)\n",
	       (unsigned int)g_gw_config.net_boot_mode);
	printf("ADC: %uch (raw/min/max), 2s window | UDP: %dms\n",
	       (unsigned)CONFIG_SMARTGATEWAY_ADC_CHANNEL_COUNT, UDP_SEND_INTERVAL_MS);

	/* ADC·RS-232: 네트워크 독립적 → 먼저 시작 */
	if (adc_task_start() != 0) {
		printf("[MAIN] Failed to create ADC task\n");
		return -1;
	}
	if (rs232_task_start() != 0) {
		printf("[MAIN] Failed to create RS-232 task\n");
		return -1;
	}

#ifdef CONFIG_SMARTGATEWAY_DI_DO_ENABLE
	if (di_do_task_start() != 0) {
		printf("[MAIN] DI/DO task start failed\n");
	}
#endif

	if (netmgr_start() != 0) {
		printf("[MAIN] netmgr_start failed\n");
		return -1;
	}

	printf("[MAIN] Waiting for network ready (max 180s)...\n");

	if (netmgr_wait_ready(180000) != 0) {
		/* 네트워크 타임아웃 — ADC·RS-232는 계속 동작, TCP·UDP만 중단 */
		printf("[MAIN] Network ready timeout — ADC/RS-232 continue without network\n");
		while (1) {
			k_sleep(K_SECONDS(60));
		}
	}

	printf("[MAIN] Network OK (%s) local IP %s\n",
	       netmgr_active_iface_label(), netmgr_local_ip());

	if (tcp_gateway_task_start() != 0) {
		printf("[MAIN] Failed to create TCP gateway task\n");
		return -1;
	}
	if (udp_task_start() != 0) {
		printf("[MAIN] Failed to create UDP task\n");
		return -1;
	}

	while (1) {
		k_sleep(K_SECONDS(60));
	}

	CODE_UNREACHABLE;
}
```

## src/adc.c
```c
/*
 * Smart Gateway - ADC 모듈 구현 (AD7327 SPI 8채널)
 *
 * - k_timer 2ms 주기로 샘플 트리거
 * - AD7327: 12-bit, ±10V (±2VREF, 내부VREF=2.5V), two's complement
 *   ADC 입력단 하드웨어 분배기 2:1 → 실제 입력범위 ±10V
 * - LPSPI6(FC6): P3_20=MOSI, P3_21=SCK, P3_22=MISO, P3_23=PCS0
 * - 2초 윈도우 min/max, UDP 20ms 전송
 *
 * AD7327 SPI 프로토콜:
 *   - 16bit MSB-first, Mode 0 (CPOL=0, CPHA=0)
 *   - 제어어 쓰기 → CS 해제(변환 시작) → 다음 전송 시 결과 읽기 (read-ahead)
 *   - 8채널 읽기: 9회 전송 (첫 결과 폐기)
 *
 * 제어어 형식:
 *   [15]=1(REG_SEL) [14:12]=ADD[2:0] [11:10]=RANGE(01=±2VREF)
 *   [9]=CODING(1=2's comp) [8]=REF_SEL(0=ext) [7:0]=0
 *
 * 결과어 형식:
 *   [15:13]=CH[2:0] [12:1]=12bit 데이터 [0]=0
 */

#include "adc.h"
#include "config_nvs.h"
#include "time_helper.h"

#include <stdio.h>
#include <string.h>
#include <zephyr/autoconf.h>
#include <zephyr/kernel.h>
#include <zephyr/sys/util.h>
#include <zephyr/drivers/spi.h>
#include <zephyr/device.h>
#include <zephyr/devicetree.h>
#include <zephyr/sys/byteorder.h>

/* ── AD7327 상수 ────────────────────────────────────────────── */
#define AD7327_NUM_CHANNELS	8
#define AD7327_RESOLUTION	12
#define AD7327_FULL_SCALE	(1 << (AD7327_RESOLUTION - 1))	/* 2048 */
#define AD7327_VREF_V		10.0f	/* ±10V 

/* AD7327 Control Register 1 (REG_SEL=00) 비트 구성:
 * bit15    = WRITE=1
 * bit14:13 = REG_SEL=00 (Control Register 1 선택)
 * bit12:10 = ADD[2:0]   = 채널번호
 * bit9:8   = MODE=00    (8채널 싱글엔드, Table 10)
 * bit7:6   = PM=00      (정상동작)
 * bit5     = Coding=0   (2의보수)
 * bit4     = Ref=1      (내부 기준전원 2.5V 사용)
 * bit3:2   = Seq=00     (직접 채널 선택, 시퀀서 없음)
 * bit1:0   = 0
 *
 * 0x8010 = bit15=1, bit9:8=00(MODE=8ch single-ended), bit4=1(내부ref)
 */
#define AD7327_CH_CTRL(ch)	((uint16_t)(0x8010U | ((uint16_t)(ch) << 10U)))


/* ── SPI 디바이스 ────────────────────────────────────────────── */
#define AD7327_NODE DT_NODELABEL(ad7327)

/* AD7327 SPI Mode 1 (CPOL=0, CPHA=1) */
static const struct spi_dt_spec s_spi = SPI_DT_SPEC_GET(
	AD7327_NODE,
	SPI_WORD_SET(16) | SPI_TRANSFER_MSB | SPI_OP_MODE_MASTER | SPI_MODE_CPHA,
	2
);

/* ── ADC 태스크 상수 ─────────────────────────────────────────── */
#define ADC_SAMPLE_MS		2
#define ADC_WINDOW_MS		2000
#define ADC_PRINT_EVERY_N	500
#define ADC_WINDOW_SAMPLES	(ADC_WINDOW_MS / ADC_SAMPLE_MS)
#define ADC_UDP_TX_INTERVAL_MS	20
#define ADC_UDP_SAMPLES_PER_PERIOD (ADC_UDP_TX_INTERVAL_MS / ADC_SAMPLE_MS)

BUILD_ASSERT((ADC_WINDOW_MS % ADC_SAMPLE_MS) == 0);
BUILD_ASSERT((ADC_UDP_TX_INTERVAL_MS % ADC_SAMPLE_MS) == 0);


/* ── 상태 변수 ───────────────────────────────────────────────── */
static adc_snapshot_t adc_snapshot;
static struct k_spinlock adc_lock;
static bool adc_has_sample;

static float running_min[ADC_MAX_CHANNELS];
static float running_max[ADC_MAX_CHANNELS];
static uint32_t window_sample_count;
static uint16_t udp_period_sample_count;
static uint16_t udp_frozen_sample_count;
static uint32_t adc_sem_give_fail;

K_THREAD_STACK_DEFINE(adc_task_stack, 8192);
static struct k_thread adc_task_data;

K_SEM_DEFINE(adc_sample_sem, 0, 128);
K_SEM_DEFINE(adc_udp_trigger_sem, 0, 1);

static void adc_sample_timer_handler(struct k_timer *timer);
K_TIMER_DEFINE(adc_sample_timer, adc_sample_timer_handler, NULL);

/* ── AD7327 SPI 헬퍼 ─────────────────────────────────────────── */

/* 16비트 단일 전송: CS 16비트 동안 LOW 유지
 * TX: ctrl_word 그대로 (LPSPI가 LE uint16_t를 bit15 먼저 전송)
 * RX: LPSPI가 수신 데이터를 LE로 저장 → sys_be16_to_cpu로 교정 */
static int ad7327_transfer(uint16_t ctrl_word, uint16_t *result)
{
	uint16_t tx = ctrl_word;
	uint16_t rx = 0;

	struct spi_buf tx_buf = { .buf = &tx, .len = sizeof(tx) };
	struct spi_buf rx_buf = { .buf = &rx, .len = sizeof(rx) };
	struct spi_buf_set tx_set = { .buffers = &tx_buf, .count = 1 };
	struct spi_buf_set rx_set = { .buffers = &rx_buf, .count = 1 };

	int ret = spi_transceive_dt(&s_spi, &tx_set, &rx_set);

	/* tCONVERT = 16×tSCLK = 1.6μs (10MHz) → 16클록 동안 변환 완료
	 * spi_transceive_dt 반환 시 이미 완료, CS딜레이(2μs)로 충분 */

	if (ret == 0 && result) {
		/* RX: LPSPI가 수신 데이터를 LE로 저장
		 * sys_be16_to_cpu 없이 raw 값 사용 (바이트 순서 실험) */
		*result = rx;
	}
	return ret;
}

/* 결과어 파싱: [15:13]=채널번호, [12:1]=12bit 2의보수, [0]=0 */
static float ad7327_result_to_volts(uint16_t raw)
{
	uint16_t data12 = (raw >> 1) & 0x0FFFU;  /* bits[12:1] */
	int16_t code = (data12 & 0x0800U)
			? (int16_t)(data12 | 0xF000U)
			: (int16_t)data12;

	return (float)code * (AD7327_VREF_V / (float)AD7327_FULL_SCALE);
}


/* 8채널 읽기 - Read-ahead (2ms 1사이클):
 * 전송N과 수신N이 동시 발생 → 9회 전송으로 8채널 처리
 *   전송0: CH0명령 → 결과 폐기 (파이프라인 준비)
 *   전송1: CH1명령 → CH0 결과 수신
 *   전송2: CH2명령 → CH1 결과 수신
 *   ...
 *   전송8: CH0명령 → CH7 결과 수신
 * 총 9회 × 11.6μs = 104μs << 2ms */
static int ad7327_read_all(float *volts)
{
	uint16_t rx = 0;
	int ret;

	/* 전송0: 파이프라인 준비 (결과 폐기) */
	ret = ad7327_transfer(AD7327_CH_CTRL(0), &rx);
	if (ret != 0) {
		return ret;
	}

	/* 전송1~7: CH[i] 명령 + CH[i-1] 결과 수신 */
	for (int i = 1; i < AD7327_NUM_CHANNELS; i++) {
		ret = ad7327_transfer(AD7327_CH_CTRL(i), &rx);
		if (ret != 0) {
			return ret;
		}
		volts[i - 1] = ad7327_result_to_volts(rx);
	}

	/* 전송8: CH0 명령 + CH7 마지막 결과 수신 */
	ret = ad7327_transfer(AD7327_CH_CTRL(0), &rx);
	if (ret != 0) {
		return ret;
	}
	volts[7] = ad7327_result_to_volts(rx);

	return 0;
}

/* ── 샘플 처리 ───────────────────────────────────────────────── */

static void adc_sample_timer_handler(struct k_timer *timer)
{
	ARG_UNUSED(timer);

	if (k_sem_count_get(&adc_sample_sem) >= 127) {
		adc_sem_give_fail++;
	} else {
		k_sem_give(&adc_sample_sem);
	}
}

static void adc_publish_sample(const float *volts)
{
	k_spinlock_key_t key = k_spin_lock(&adc_lock);

	for (uint8_t i = 0; i < AD7327_NUM_CHANNELS; i++) {
		float v = volts[i];

		if (v < running_min[i]) {
			running_min[i] = v;
		}
		if (v > running_max[i]) {
			running_max[i] = v;
		}
		adc_snapshot.raw[i]     = v;
		adc_snapshot.min_val[i] = running_min[i];
		adc_snapshot.max_val[i] = running_max[i];
	}

	adc_snapshot.ch_count     = AD7327_NUM_CHANNELS;
	adc_snapshot.sample_count = udp_period_sample_count;
	get_datetime_ms(&adc_snapshot.datetime, &adc_snapshot.msec);

	k_spin_unlock(&adc_lock, key);
	adc_has_sample = true;
}

static void adc_begin_next_window(const float *volts)
{
	for (uint8_t i = 0; i < AD7327_NUM_CHANNELS; i++) {
		running_min[i] = volts[i];
		running_max[i] = volts[i];
	}
	window_sample_count = 0;
}

static void adc_process_one_sample(void)
{
	float volts[AD7327_NUM_CHANNELS];
	int ret = ad7327_read_all(volts);

	if (ret != 0) {
		printf("[ADC] AD7327 SPI read error: %d\n", ret);
		return;
	}

	if (udp_period_sample_count < 0xFFFFU) {
		udp_period_sample_count++;
	}
	window_sample_count++;
	adc_publish_sample(volts);

	if (window_sample_count >= ADC_WINDOW_SAMPLES) {
		adc_begin_next_window(volts);
	}

	if (udp_period_sample_count >= ADC_UDP_SAMPLES_PER_PERIOD) {
		k_spinlock_key_t tkey = k_spin_lock(&adc_lock);

		udp_frozen_sample_count = udp_period_sample_count;
		udp_period_sample_count = 0;
		k_spin_unlock(&adc_lock, tkey);
		k_sem_give(&adc_udp_trigger_sem);
	}
}

/* ── ADC 태스크 ──────────────────────────────────────────────── */

static void adc_task(void *p1, void *p2, void *p3)
{
	ARG_UNUSED(p1);
	ARG_UNUSED(p2);
	ARG_UNUSED(p3);

	if (!spi_is_ready_dt(&s_spi)) {
		printf("[ADC] AD7327 SPI not ready\n");
		return;
	}

	for (int i = 0; i < ADC_MAX_CHANNELS; i++) {
		running_min[i] = 999.0f;
		running_max[i] = -999.0f;
	}
	window_sample_count     = 0;
	udp_period_sample_count = 0;
	adc_sem_give_fail       = 0;

	strncpy(adc_snapshot.line, g_gw_config.master_code, ADC_LINE_ID_MAX_CHARS);
	adc_snapshot.line[ADC_LINE_ID_MAX_CHARS] = '\0';

	printf("[ADC] AD7327 8ch ±10V (SPI LPSPI6 P3_20-23)"
	       " %dms sample, %dms min/max, UDP %dms\n",
	       ADC_SAMPLE_MS, ADC_WINDOW_MS, ADC_UDP_TX_INTERVAL_MS);

	k_timer_start(&adc_sample_timer, K_MSEC(ADC_SAMPLE_MS), K_MSEC(ADC_SAMPLE_MS));

	while (1) {
		(void)k_sem_take(&adc_sample_sem, K_FOREVER);

		do {
			adc_process_one_sample();
		} while (k_sem_take(&adc_sample_sem, K_NO_WAIT) == 0);

		if (adc_sem_give_fail > 0U &&
		    (adc_sem_give_fail % ADC_PRINT_EVERY_N) == 0U) {
			printf("[ADC] sample sem overflow (lost ticks): %u\n",
			       (unsigned)adc_sem_give_fail);
		}
	}
}

/* ── 공개 API ────────────────────────────────────────────────── */

int adc_get_latest(adc_snapshot_t *out)
{
	if (!out || !adc_has_sample) {
		return -1;
	}
	k_spinlock_key_t key = k_spin_lock(&adc_lock);

	memcpy(out, &adc_snapshot, sizeof(adc_snapshot_t));
	out->sample_count = udp_frozen_sample_count;
	k_spin_unlock(&adc_lock, key);
	return 0;
}

int adc_task_start(void)
{
	k_tid_t tid = k_thread_create(&adc_task_data, adc_task_stack,
				      K_THREAD_STACK_SIZEOF(adc_task_stack),
				      adc_task, NULL, NULL, NULL, 0, 0, K_NO_WAIT);

	if (tid == NULL) {
		return -1;
	}
	k_thread_name_set(tid, "adc_task");
	return 0;
}
```

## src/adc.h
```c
/*
 * Smart Gateway - ADC 모듈 헤더
 *
 * [역할]
 * AD7327 외부 SPI ADC (8채널 ±10V)를 사용하는 인터페이스 선언.
 * adc_task_start() 로 샘플링 스레드를 시작하고,
 * adc_get_latest() 로 최신 스냅샷을 읽습니다.
 *
 * [핀 연결] LPSPI6 (FlexComm6, MikroBUS SPI)
 *   P3_20=MOSI  P3_21=SCLK  P3_22=MISO  P3_23=CS(PCS0)
 */

#ifndef ADC_H
#define ADC_H

#include <stdint.h>
#include <zephyr/kernel.h>

#define ADC_MAX_CHANNELS  8

/* line / DeviceID: 본문 최대 50자 + NUL (Kconfig SMARTGATEWAY_LINE_ID 등) */
#define ADC_LINE_ID_MAX_CHARS  50
#define ADC_LINE_MAX_LEN       (ADC_LINE_ID_MAX_CHARS + 1)

/* 날짜/시간 (년/월/일/시/분/초) */
typedef struct {
	uint16_t year;   /* 2000~2099 */
	uint8_t  month;  /* 1~12 */
	uint8_t  day;    /* 1~31 */
	uint8_t  hour;   /* 0~23 */
	uint8_t  min;    /* 0~59 */
	uint8_t  sec;    /* 0~59 */
} datetime_t;

/* ADC 스냅샷 — 2ms 샘플, 2s min/max 윈도우, UDP는 20ms마다 최신 raw+min/max 전송 */
typedef struct {
	char       line[ADC_LINE_MAX_LEN];       /* 라인 ID 문자열, NUL 종료 (NVS master_code와 동기) */
	datetime_t datetime;                     /* 전송 시각 (초) */
	uint16_t   msec;                         /* UDP 타임스탬프 17자(밀리초 3자)용 */
	uint16_t   sample_count;                 /* since last UDP TX (~20ms / 2ms ≈ 10) */
	float      raw[ADC_MAX_CHANNELS];        /* 최신 샘플 전압 (V, 0~Vref) */
	float      min_val[ADC_MAX_CHANNELS];    /* 2초 윈도우 최소 전압 (V) */
	float      max_val[ADC_MAX_CHANNELS];    /* 2초 윈도우 최대 전압 (V) */
	uint8_t    ch_count;                     /* 2~8 */
} adc_snapshot_t;

/*
 * UDP 전송 트리거 세마포어 — ADC 태스크가 N샘플마다 give, UDP 태스크가 take.
 * udp.c에서 k_msleep(20ms) 대신 이 세마포어를 기다려 타이밍 지터를 제거한다.
 */
extern struct k_sem adc_udp_trigger_sem;

/*
 * adc_task_start
 *
 * ADC 샘플링을 수행하는 전용 스레드를 생성하고 시작합니다.
 * k_timer(2ms)로 ADC를 읽고, 매 샘플 공유 스냅샷(raw·min·max)을 갱신합니다.
 *
 */
int adc_task_start(void);

/*
 * adc_get_latest
 *
 * 현재 ADC 스냅샷의 복사본을 반환합니다.
 * UDP Task 등에서 호출하여 최신값을 읽습니다.
 */
int adc_get_latest(adc_snapshot_t *out);

#endif /* ADC_H */
```

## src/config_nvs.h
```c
/*
 * SmartGateway — 런타임 설정 (NVS 영속 + 시리얼 메뉴)
 *
 * 목표: 장치코드(master_code)·인덱스(device_index, NVS 예약)·WiFi/ETH 주소·net_boot_mode
 * 를 플래시에 두고, 저장(S) 후 재부팅하면 선택 모드로 동작. (device_index는 UDP 페이로드와 무관)
 *
 * config_nvs_load() → Kconfig 기본값 후 NVS 덮어쓰기
 * config_nvs_menu() → 부팅 시 키 입력 시 편집
 * config_nvs_save() → NVS 기록
 */

#ifndef CONFIG_NVS_H
#define CONFIG_NVS_H

#include <stdint.h>

typedef struct {
	char     master_code[32];
	/* NVS 예약 필드(추후 프로토콜용). UDP MessagePack과는 무관 */
	uint16_t device_index;

	/* ── ETH 설정 ── */
	char     eth_ip[16];
	char     eth_netmask[16];
	char     eth_gw[16];
	char     eth_tcp_server_ip[16];
	uint16_t eth_tcp_server_port;
	char     eth_udp_server_ip[16];
	uint16_t eth_udp_server_port;

	/* ── WiFi 설정 ── */
	char     wifi_ssid[33];
	char     wifi_psk[65];
	char     wifi_ip[16];
	char     wifi_netmask[16];
	char     wifi_gw[16];
	char     wifi_tcp_server_ip[16];
	uint16_t wifi_tcp_server_port;
	char     wifi_udp_server_ip[16];
	uint16_t wifi_udp_server_port;

	/* NVS 영속: 0=WiFi 모드 1=이더넷 모드 (WiFi 실패 시 NVS를 1로 저장 후 재부팅) */
	uint8_t  net_boot_mode;

	/* 가스 센서 모델: 0=없음 1=O2-SM30 2=H2S-SM30 3=CO-SM30 4=S-300-3V 5=미정 */
	uint8_t  sensor_model_usb1; /* USB1(EHCI) 포트 */
	uint8_t  sensor_model_usb0; /* USB0(KHCI) 포트 */
} gw_config_t;

#define GW_NET_BOOT_WIFI 0U
#define GW_NET_BOOT_ETH  1U

extern gw_config_t g_gw_config;

void config_nvs_load(void);
void config_nvs_save(void);
void config_nvs_save_boot_mode(void);
void config_nvs_menu(void);

#endif /* CONFIG_NVS_H */
```

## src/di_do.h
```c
/*
 * SmartGateway — DI/DO I2C GPIO 확장기 (PCA9554DB)
 *
 * DO: LPI2C1(FC1) P0_20/P0_21 → PCA9554DB(0x22) 8채널 디지털 출력
 * DI: LPI2C7(FC7) P3_2/P3_3   → PCA9554DB(0x21) 8채널 디지털 입력
 * EXT_PWR1: P0_24, EXT_PWR2: P0_25 (GPIO0 출력)
 * DO_INT:   P3_0,  DI_INT:   P3_1  (GPIO3 입력, 향후 인터럽트 확장)
 */

#ifndef DI_DO_H
#define DI_DO_H

#include <stdint.h>
#include <stdbool.h>

/* 하드웨어 초기화 (main에서 nvs 메뉴 전에 호출) */
int  di_do_init(void);

/* 백그라운드 폴링 태스크 시작 (init 후 호출) */
int  di_do_task_start(void);

/* DO: 8비트 출력 마스크 설정/읽기 (bit0=DO0 … bit7=DO7) */
int     do_set(uint8_t mask);
uint8_t do_get(void);

/* DI: 8비트 입력 읽기 (직접 I2C) / 캐시된 최신 값 반환 */
int     di_read(uint8_t *val);
uint8_t di_get(void);

/* 외부 전원 제어/읽기 */
void ext_pwr1_set(bool on);
void ext_pwr2_set(bool on);
bool ext_pwr1_get(void);
bool ext_pwr2_get(void);

#endif /* DI_DO_H */
```
